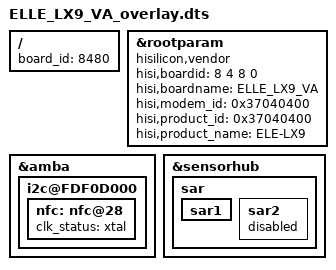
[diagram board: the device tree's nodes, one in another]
/**
 * Copyright (C) 2014 Hisilicon Ltd.
 *
 *  This program is free software; you can redistribute it and/or modify
 *  it under the terms of the GNU General Public License version 2 as
 *  publishhed by the Free Software Foundation.
 */

/dts-v1/;
/plugin/;
/include/ "ELLE_TUGL_VA_overlay.dtsi"

/ {
    board_id = <8480>;
};
    &rootparam{
		compatible = "hisilicon,vendor";
		hisi,boardid = <8 4 8 0>;
		hisi,boardname = "ELLE_LX9_VA";
		hisi,modem_id = <0x37040400>;
		hisi,product_id = <0x37040400>;
		hisi,product_name = "ELE-LX9";
	};
    &amba {
		i2c@FDF0D000 {
				nfc:nfc@28{
						clk_status = "xtal";
				};
		};
    };
    &sensorhub{
            sar{
                    sar1{
                            status = "ok";
                    };
                    sar2{
                            status = "disabled";
                    };
            };
    };
